AUTOSAR XML (schema 314)
package /ComponentType
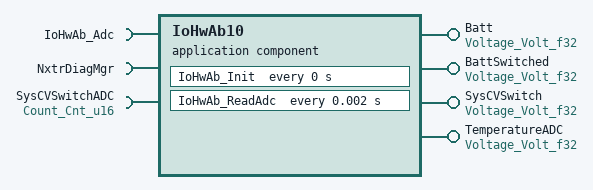
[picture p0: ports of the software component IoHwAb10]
  application software component type IoHwAb10
    4 x provide port, all with unqueued-sender-com-spec{data-element=Volt_f32, can-invalidate=false, init-value=D_ZERO_ULS_F32}, provided-interface=Voltage_Volt_f32:
      Batt
      BattSwitched
      SysCVSwitch
      TemperatureADC
    require port IoHwAb_Adc: client-com-spec=ResetAdcEnable, required-interface=IoHwAb_Adc
    require port NxtrDiagMgr: required-com-specs=[GetNTCActive, GetNTCFailed, GetNTCStatus, SetNTCStatus], required-interface=NxtrDiagMgr
    require port SysCVSwitchADC: unqueued-receiver-com-spec{data-element=Cnt_u16, init-value=D_ZERO_CNT_U16}, required-interface=Count_Cnt_u16
  internal behavior IoHwAb10_InternalBehavior: component=IoHwAb10
    timing event IoHwAb_InitEvent: start-on-event=IoHwAb_Init, period=0
    timing event TMT_IoHwAb_ReadAdc: start-on-event=IoHwAb_ReadAdc, period=0.002
    port-api-options:
      enable-take-address=false, indirect-api=false, port=Batt
      enable-take-address=false, indirect-api=false, port=BattSwitched
      enable-take-address=false, indirect-api=false, port=IoHwAb_Adc
      enable-take-address=false, indirect-api=false, port=NxtrDiagMgr
      enable-take-address=false, indirect-api=false, port=SysCVSwitch
      enable-take-address=false, indirect-api=false, port=SysCVSwitchADC
      enable-take-address=false, indirect-api=false, port=TemperatureADC
    runnable IoHwAb_Init
      4 x data write access:
        WRITE_Batt_Volt_f32: data-element=Batt.Volt_f32
        WRITE_BattSwitched_Volt_f32: data-element=BattSwitched.Volt_f32
        WRITE_SysCVSwitch_Volt_f32: data-element=SysCVSwitch.Volt_f32
        WRITE_TemperatureADC_Volt_f32: data-element=TemperatureADC.Volt_f32
    runnable IoHwAb_ReadAdc
      data read access READ_SysCVSwitchADC_Cnt_u16: data-element=SysCVSwitchADC.Cnt_u16
      4 x data write access:
        WRITE_Batt_Volt_f32: data-element=Batt.Volt_f32
        WRITE_BattSwitched_Volt_f32: data-element=BattSwitched.Volt_f32
        WRITE_SysCVSwitch_Volt_f32: data-element=SysCVSwitch.Volt_f32
        WRITE_TemperatureADC_Volt_f32: data-element=TemperatureADC.Volt_f32
      sync call SC_IoHwAb_Adc_ResetAdcEnable: operation=IoHwAb_Adc.ResetAdcEnable, timeout=0
      sync call SC_NxtrDiagMgr_SetNTCStatus: operation=NxtrDiagMgr.SetNTCStatus, timeout=0
  swc implementation IoHwAb10_Implementation: behavior=IoHwAb10_InternalBehavior
    code-descriptors:
      code Code: type=SRC
